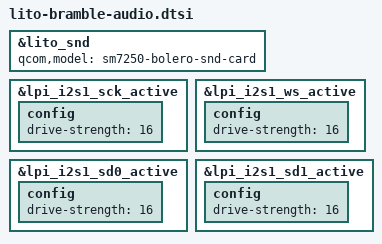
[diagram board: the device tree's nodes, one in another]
// SPDX-License-Identifier: GPL-2.0
/* Copyright (c) 2019, The Linux Foundation. All rights reserved.
 *
 * This program is free software; you can redistribute it and/or modify
 * it under the terms of the GNU General Public License version 2 and
 * only version 2 as published by the Free Software Foundation.
 *
 * This program is distributed in the hope that it will be useful,
 * but WITHOUT ANY WARRANTY; without even the implied warranty of
 * MERCHANTABILITY or FITNESS FOR A PARTICULAR PURPOSE.  See the
 * GNU General Public License for more details.
 */
&lito_snd {
	qcom,model = "sm7250-bolero-snd-card";
};

&lpi_i2s1_sck_active { /* gpio6 */
	config {
		drive-strength = <16>; /*16mA*/
	};
};

&lpi_i2s1_ws_active { /* gpio7 */
	config {
		drive-strength = <16>; /*16mA*/
	};
};

&lpi_i2s1_sd0_active { /* gpio8 */
	config {
		drive-strength = <16>; /*16mA*/
	};
};

&lpi_i2s1_sd1_active { /* gpio9 */
	config {
		drive-strength = <16>; /*16mA*/
	};
};
